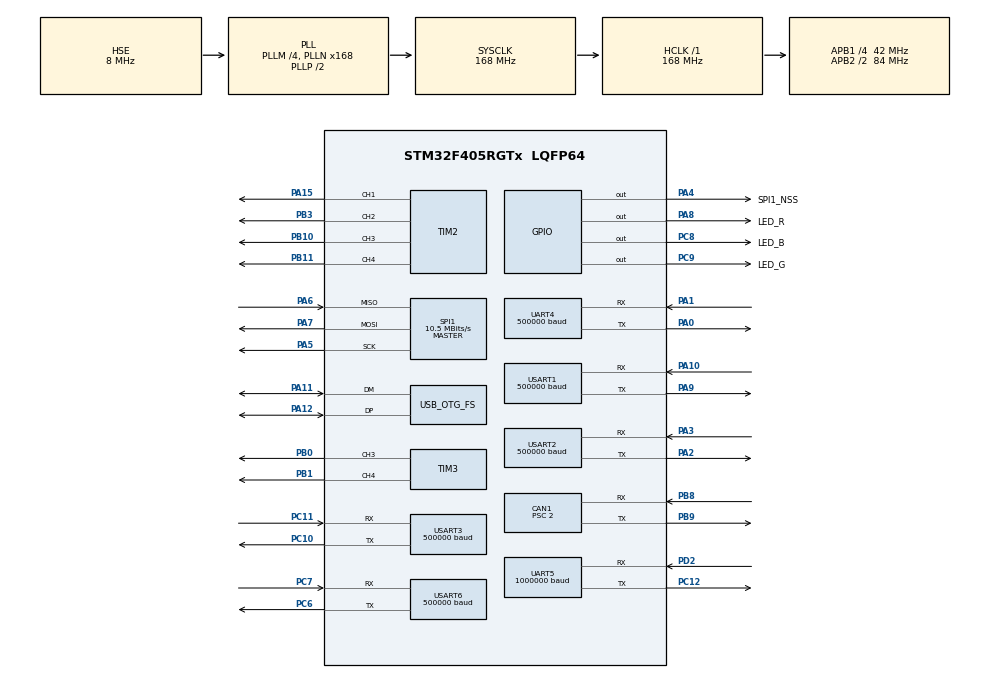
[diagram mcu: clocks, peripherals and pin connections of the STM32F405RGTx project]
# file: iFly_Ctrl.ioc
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CAN1.BS1=CAN_BS1_16TQ
CAN1.BS2=CAN_BS2_4TQ
CAN1.CalculateBaudRate=1000000
CAN1.CalculateTimeBit=1000
CAN1.CalculateTimeQuantum=47.61904761904762
CAN1.Mode=CAN_MODE_LOOPBACK
CAN1.Prescaler=2
Dma.Request0=UART4_RX
Dma.Request1=UART4_TX
Dma.Request10=USART6_RX
Dma.Request11=USART6_TX
Dma.Request2=UART5_RX
Dma.Request3=UART5_TX
Dma.Request4=USART1_RX
Dma.Request5=USART1_TX
Dma.Request6=USART2_RX
Dma.Request7=USART2_TX
Dma.Request8=USART3_RX
Dma.Request9=USART3_TX
Dma.UART4_RX.0.Direction=DMA_PERIPH_TO_MEMORY
Dma.UART4_RX.0.FIFOMode=DMA_FIFOMODE_DISABLE
Dma.UART4_RX.0.Instance=DMA1_Stream2
Dma.UART4_RX.0.MemDataAlignment=DMA_MDATAALIGN_BYTE
Dma.UART4_RX.0.MemInc=DMA_MINC_ENABLE
Dma.UART4_RX.0.Mode=DMA_CIRCULAR
Dma.UART4_RX.0.PeriphDataAlignment=DMA_PDATAALIGN_BYTE
Dma.UART4_RX.0.PeriphInc=DMA_PINC_DISABLE
Dma.UART4_RX.0.Priority=DMA_PRIORITY_LOW
Dma.UART4_TX.1.Direction=DMA_MEMORY_TO_PERIPH
Dma.UART4_TX.1.FIFOMode=DMA_FIFOMODE_DISABLE
Dma.UART4_TX.1.Instance=DMA1_Stream4
Dma.UART4_TX.1.MemDataAlignment=DMA_MDATAALIGN_BYTE
Dma.UART4_TX.1.MemInc=DMA_MINC_ENABLE
Dma.UART4_TX.1.Mode=DMA_NORMAL
Dma.UART4_TX.1.PeriphDataAlignment=DMA_PDATAALIGN_BYTE
Dma.UART4_TX.1.PeriphInc=DMA_PINC_DISABLE
Dma.UART4_TX.1.Priority=DMA_PRIORITY_LOW
Dma.UART5_RX.2.Direction=DMA_PERIPH_TO_MEMORY
Dma.UART5_RX.2.FIFOMode=DMA_FIFOMODE_DISABLE
Dma.UART5_RX.2.Instance=DMA1_Stream0
Dma.UART5_RX.2.MemDataAlignment=DMA_MDATAALIGN_BYTE
Dma.UART5_RX.2.MemInc=DMA_MINC_ENABLE
Dma.UART5_RX.2.Mode=DMA_CIRCULAR
Dma.UART5_RX.2.PeriphDataAlignment=DMA_PDATAALIGN_BYTE
Dma.UART5_RX.2.PeriphInc=DMA_PINC_DISABLE
Dma.UART5_RX.2.Priority=DMA_PRIORITY_LOW
Dma.UART5_TX.3.Direction=DMA_MEMORY_TO_PERIPH
Dma.UART5_TX.3.FIFOMode=DMA_FIFOMODE_DISABLE
Dma.UART5_TX.3.Instance=DMA1_Stream7
Dma.UART5_TX.3.MemDataAlignment=DMA_MDATAALIGN_BYTE
Dma.UART5_TX.3.MemInc=DMA_MINC_ENABLE
Dma.UART5_TX.3.Mode=DMA_NORMAL
Dma.UART5_TX.3.PeriphDataAlignment=DMA_PDATAALIGN_BYTE
Dma.UART5_TX.3.PeriphInc=DMA_PINC_DISABLE
Dma.UART5_TX.3.Priority=DMA_PRIORITY_LOW
Dma.USART1_RX.4.Direction=DMA_PERIPH_TO_MEMORY
Dma.USART1_RX.4.FIFOMode=DMA_FIFOMODE_DISABLE
Dma.USART1_RX.4.Instance=DMA2_Stream2
Dma.USART1_RX.4.MemDataAlignment=DMA_MDATAALIGN_BYTE
Dma.USART1_RX.4.MemInc=DMA_MINC_ENABLE
Dma.USART1_RX.4.Mode=DMA_CIRCULAR
Dma.USART1_RX.4.PeriphDataAlignment=DMA_PDATAALIGN_BYTE
Dma.USART1_RX.4.PeriphInc=DMA_PINC_DISABLE
Dma.USART1_RX.4.Priority=DMA_PRIORITY_LOW
Dma.USART1_TX.5.Direction=DMA_MEMORY_TO_PERIPH
Dma.USART1_TX.5.FIFOMode=DMA_FIFOMODE_DISABLE
Dma.USART1_TX.5.Instance=DMA2_Stream7
Dma.USART1_TX.5.MemDataAlignment=DMA_MDATAALIGN_BYTE
Dma.USART1_TX.5.MemInc=DMA_MINC_ENABLE
Dma.USART1_TX.5.Mode=DMA_NORMAL
Dma.USART1_TX.5.PeriphDataAlignment=DMA_PDATAALIGN_BYTE
Dma.USART1_TX.5.PeriphInc=DMA_PINC_DISABLE
Dma.USART1_TX.5.Priority=DMA_PRIORITY_LOW
Dma.USART2_RX.6.Direction=DMA_PERIPH_TO_MEMORY
Dma.USART2_RX.6.FIFOMode=DMA_FIFOMODE_DISABLE
Dma.USART2_RX.6.Instance=DMA1_Stream5
Dma.USART2_RX.6.MemDataAlignment=DMA_MDATAALIGN_BYTE
Dma.USART2_RX.6.MemInc=DMA_MINC_ENABLE
Dma.USART2_RX.6.Mode=DMA_CIRCULAR
Dma.USART2_RX.6.PeriphDataAlignment=DMA_PDATAALIGN_BYTE
Dma.USART2_RX.6.PeriphInc=DMA_PINC_DISABLE
Dma.USART2_RX.6.Priority=DMA_PRIORITY_LOW
Dma.USART2_TX.7.Direction=DMA_MEMORY_TO_PERIPH
Dma.USART2_TX.7.FIFOMode=DMA_FIFOMODE_DISABLE
Dma.USART2_TX.7.Instance=DMA1_Stream6
Dma.USART2_TX.7.MemDataAlignment=DMA_MDATAALIGN_BYTE
Dma.USART2_TX.7.MemInc=DMA_MINC_ENABLE
Dma.USART2_TX.7.Mode=DMA_NORMAL
Dma.USART2_TX.7.PeriphDataAlignment=DMA_PDATAALIGN_BYTE
Dma.USART2_TX.7.PeriphInc=DMA_PINC_DISABLE
Dma.USART2_TX.7.Priority=DMA_PRIORITY_LOW
Dma.USART3_RX.8.Direction=DMA_PERIPH_TO_MEMORY
Dma.USART3_RX.8.FIFOMode=DMA_FIFOMODE_DISABLE
Dma.USART3_RX.8.Instance=DMA1_Stream1
Dma.USART3_RX.8.MemDataAlignment=DMA_MDATAALIGN_BYTE
Dma.USART3_RX.8.MemInc=DMA_MINC_ENABLE
Dma.USART3_RX.8.Mode=DMA_CIRCULAR
Dma.USART3_RX.8.PeriphDataAlignment=DMA_PDATAALIGN_BYTE
Dma.USART3_RX.8.PeriphInc=DMA_PINC_DISABLE
Dma.USART3_RX.8.Priority=DMA_PRIORITY_LOW
Dma.USART3_TX.9.Direction=DMA_MEMORY_TO_PERIPH
Dma.USART3_TX.9.FIFOMode=DMA_FIFOMODE_DISABLE
Dma.USART3_TX.9.Instance=DMA1_Stream3
Dma.USART3_TX.9.MemDataAlignment=DMA_MDATAALIGN_BYTE
Dma.USART3_TX.9.MemInc=DMA_MINC_ENABLE
Dma.USART3_TX.9.Mode=DMA_NORMAL
Dma.USART3_TX.9.PeriphDataAlignment=DMA_PDATAALIGN_BYTE
Dma.USART3_TX.9.PeriphInc=DMA_PINC_DISABLE
Dma.USART3_TX.9.Priority=DMA_PRIORITY_LOW
Dma.USART6_RX.10.Direction=DMA_PERIPH_TO_MEMORY
Dma.USART6_RX.10.FIFOMode=DMA_FIFOMODE_DISABLE
Dma.USART6_RX.10.Instance=DMA2_Stream1
Dma.USART6_RX.10.MemDataAlignment=DMA_MDATAALIGN_BYTE
Dma.USART6_RX.10.MemInc=DMA_MINC_ENABLE
Dma.USART6_RX.10.Mode=DMA_CIRCULAR
Dma.USART6_RX.10.PeriphDataAlignment=DMA_PDATAALIGN_BYTE
Dma.USART6_RX.10.PeriphInc=DMA_PINC_DISABLE
Dma.USART6_RX.10.Priority=DMA_PRIORITY_LOW
Dma.USART6_TX.11.Direction=DMA_MEMORY_TO_PERIPH
Dma.USART6_TX.11.FIFOMode=DMA_FIFOMODE_DISABLE
Dma.USART6_TX.11.Instance=DMA2_Stream6
Dma.USART6_TX.11.MemDataAlignment=DMA_MDATAALIGN_BYTE
Dma.USART6_TX.11.MemInc=DMA_MINC_ENABLE
Dma.USART6_TX.11.Mode=DMA_NORMAL
Dma.USART6_TX.11.PeriphDataAlignment=DMA_PDATAALIGN_BYTE
Dma.USART6_TX.11.PeriphInc=DMA_PINC_DISABLE
Dma.USART6_TX.11.Priority=DMA_PRIORITY_LOW
Mcu.Family=STM32F4
Mcu.Name=STM32F405RGTx
Mcu.Package=LQFP64
NVIC.CAN1_RX0_IRQn=true\:0\:0\:false\:false\:true\:true\:true\:true
NVIC.CAN1_RX1_IRQn=true\:0\:0\:false\:false\:true\:true\:true\:true
NVIC.CAN1_SCE_IRQn=true\:0\:0\:false\:false\:true\:true\:true\:true
NVIC.CAN1_TX_IRQn=true\:0\:0\:true\:false\:true\:true\:true\:true
NVIC.DMA1_Stream0_IRQn=true\:0\:0\:false\:false\:true\:false\:true\:true
NVIC.DMA1_Stream1_IRQn=true\:0\:0\:false\:false\:true\:false\:true\:true
NVIC.DMA1_Stream2_IRQn=true\:0\:0\:false\:false\:true\:false\:true\:true
NVIC.DMA1_Stream3_IRQn=true\:0\:0\:false\:false\:true\:false\:true\:true
NVIC.DMA1_Stream4_IRQn=true\:0\:0\:false\:false\:true\:false\:true\:true
NVIC.DMA1_Stream5_IRQn=true\:0\:0\:false\:false\:true\:false\:true\:true
NVIC.DMA1_Stream6_IRQn=true\:0\:0\:false\:false\:true\:false\:true\:true
NVIC.DMA1_Stream7_IRQn=true\:0\:0\:false\:false\:true\:false\:true\:true
NVIC.DMA2_Stream1_IRQn=true\:0\:0\:false\:false\:true\:false\:true\:true
NVIC.DMA2_Stream2_IRQn=true\:0\:0\:false\:false\:true\:false\:true\:true
NVIC.DMA2_Stream6_IRQn=true\:0\:0\:false\:false\:true\:false\:true\:true
NVIC.DMA2_Stream7_IRQn=true\:0\:0\:false\:false\:true\:false\:true\:true
NVIC.OTG_FS_IRQn=true\:0\:0\:false\:false\:true\:true\:true\:true
NVIC.PriorityGroup=NVIC_PRIORITYGROUP_4
NVIC.UART4_IRQn=true\:1\:0\:true\:false\:true\:true\:true\:true
NVIC.UART5_IRQn=true\:1\:0\:true\:false\:true\:true\:true\:true
NVIC.USART1_IRQn=true\:1\:0\:true\:false\:true\:true\:true\:true
NVIC.USART2_IRQn=true\:1\:0\:true\:false\:true\:true\:true\:true
NVIC.USART3_IRQn=true\:1\:0\:true\:false\:true\:true\:true\:true
NVIC.USART6_IRQn=true\:1\:0\:true\:false\:true\:true\:true\:true
PA0-WKUP.Mode=Asynchronous
PA0-WKUP.Signal=UART4_TX
PA1.Mode=Asynchronous
PA1.Signal=UART4_RX
PA10.Mode=Asynchronous
PA10.Signal=USART1_RX
PA11.Mode=Device_Only
PA11.Signal=USB_OTG_FS_DM
PA12.Mode=Device_Only
PA12.Signal=USB_OTG_FS_DP
PA13.Mode=Serial_Wire
PA13.Signal=SYS_JTMS-SWDIO
PA14.Mode=Serial_Wire
PA14.Signal=SYS_JTCK-SWCLK
PA15.Signal=S_TIM2_CH1_ETR
PA2.Mode=Asynchronous
PA2.Signal=USART2_TX
PA3.Mode=Asynchronous
PA3.Signal=USART2_RX
PA4.GPIO_Label=SPI1_NSS
PA4.Signal=GPIO_Output
PA5.Mode=Full_Duplex_Master
PA5.Signal=SPI1_SCK
PA6.Mode=Full_Duplex_Master
PA6.Signal=SPI1_MISO
PA7.Mode=Full_Duplex_Master
PA7.Signal=SPI1_MOSI
PA8.GPIO_Label=LED_R
PA8.Signal=GPIO_Output
PA9.Mode=Asynchronous
PA9.Signal=USART1_TX
PB0.Signal=S_TIM3_CH3
PB1.Signal=S_TIM3_CH4
PB10.Signal=S_TIM2_CH3
PB11.Signal=S_TIM2_CH4
PB3.Signal=S_TIM2_CH2
PB8.Mode=CAN_Activate
PB8.Signal=CAN1_RX
PB9.Mode=CAN_Activate
PB9.Signal=CAN1_TX
PC10.Mode=Asynchronous
PC10.Signal=USART3_TX
PC11.Mode=Asynchronous
PC11.Signal=USART3_RX
PC12.Mode=Asynchronous
PC12.Signal=UART5_TX
PC6.Mode=Asynchronous
PC6.Signal=USART6_TX
PC7.Mode=Asynchronous
PC7.Signal=USART6_RX
PC8.GPIO_Label=LED_B
PC8.Signal=GPIO_Output
PC9.GPIO_Label=LED_G
PC9.Signal=GPIO_Output
PD2.Mode=Asynchronous
PD2.Signal=UART5_RX
PH0-OSC_IN.Mode=HSE-External-Oscillator
PH0-OSC_IN.Signal=RCC_OSC_IN
PH1-OSC_OUT.Mode=HSE-External-Oscillator
PH1-OSC_OUT.Signal=RCC_OSC_OUT
ProjectManager.HeapSize=0x200
ProjectManager.StackSize=0x400
ProjectManager.TargetToolchain=CMake
RCC.48MHZClocksFreq_Value=48000000
RCC.AHBFreq_Value=168000000
RCC.APB1CLKDivider=RCC_HCLK_DIV4
RCC.APB1Freq_Value=42000000
RCC.APB1TimFreq_Value=84000000
RCC.APB2CLKDivider=RCC_HCLK_DIV2
RCC.APB2Freq_Value=84000000
RCC.APB2TimFreq_Value=168000000
RCC.CortexFreq_Value=168000000
RCC.HCLKFreq_Value=168000000
RCC.HSE_VALUE=8000000
RCC.HSI_VALUE=16000000
RCC.LSE_VALUE=32768
RCC.PLLM=4
RCC.PLLN=168
RCC.PLLQ=7
RCC.SYSCLKFreq_VALUE=168000000
RCC.SYSCLKSource=RCC_SYSCLKSOURCE_PLLCLK
RCC.VCOOutputFreq_Value=336000000
SH.S_TIM2_CH1_ETR.0=TIM2_CH1,PWM Generation1 CH1
SH.S_TIM2_CH2.0=TIM2_CH2,PWM Generation2 CH2
SH.S_TIM2_CH3.0=TIM2_CH3,PWM Generation3 CH3
SH.S_TIM2_CH4.0=TIM2_CH4,PWM Generation4 CH4
SH.S_TIM3_CH3.0=TIM3_CH3,PWM Generation3 CH3
SH.S_TIM3_CH4.0=TIM3_CH4,PWM Generation4 CH4
SPI1.BaudRatePrescaler=SPI_BAUDRATEPRESCALER_8
SPI1.CalculateBaudRate=10.5 MBits/s
SPI1.Direction=SPI_DIRECTION_2LINES
SPI1.Mode=SPI_MODE_MASTER
SPI1.VirtualType=VM_MASTER
TIM2.Channel-PWM\ Generation1\ CH1=TIM_CHANNEL_1
TIM2.Channel-PWM\ Generation2\ CH2=TIM_CHANNEL_2
TIM2.Channel-PWM\ Generation3\ CH3=TIM_CHANNEL_3
TIM2.Channel-PWM\ Generation4\ CH4=TIM_CHANNEL_4
TIM3.Channel-PWM\ Generation1\ CH1=TIM_CHANNEL_1
TIM3.Channel-PWM\ Generation2\ CH2=TIM_CHANNEL_2
TIM3.Channel-PWM\ Generation3\ CH3=TIM_CHANNEL_3
TIM3.Channel-PWM\ Generation4\ CH4=TIM_CHANNEL_4
UART4.BaudRate=500000
UART4.VirtualMode=Asynchronous
UART5.BaudRate=1000000
UART5.VirtualMode=Asynchronous
USART1.BaudRate=500000
USART1.VirtualMode=VM_ASYNC
USART2.BaudRate=500000
USART2.VirtualMode=VM_ASYNC
USART3.BaudRate=500000
USART3.VirtualMode=VM_ASYNC
USART6.BaudRate=500000
USART6.VirtualMode=VM_ASYNC
USB_OTG_FS.VirtualMode=Device_Only
VP_TIM2_VS_ClockSourceINT.Mode=Internal
VP_TIM3_VS_ClockSourceINT.Mode=Internal
board=custom

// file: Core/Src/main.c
/* USER CODE BEGIN Header */
/**
  ******************************************************************************
  * @file           : main.c
  * @brief          : Main program body
  ******************************************************************************
  * @attention
  *
  * Copyright (c) 2026 STMicroelectronics.
  * All rights reserved.
  *
  * This software is licensed under terms that can be found in the LICENSE file
  * in the root directory of this software component.
  * If no LICENSE file comes with this software, it is provided AS-IS.
  *
  ******************************************************************************
  */
/* USER CODE END Header */
#include "main.h"
#include "can.h"
#include "dma.h"
#include "spi.h"
#include "tim.h"
#include "usart.h"
#include "usb_otg.h"
#include "gpio.h"

/* USER CODE BEGIN Includes */
#include "app_main.h"

/* USER CODE END Includes */

void SystemClock_Config(void);

int main(void)
{

  /* MCU Configuration--------------------------------------------------------*/

  /* Reset of all peripherals, Initializes the Flash interface and the Systick. */
  HAL_Init();

  /* Configure the system clock */
  SystemClock_Config();

  /* Initialize all configured peripherals */
  MX_GPIO_Init();
  MX_DMA_Init();
  MX_USB_OTG_FS_PCD_Init();
  MX_UART4_Init();
  MX_UART5_Init();
  MX_USART1_UART_Init();
  MX_USART2_UART_Init();
  MX_USART3_UART_Init();
  MX_USART6_UART_Init();
  MX_CAN1_Init();
  MX_TIM2_Init();
  MX_TIM3_Init();
  MX_SPI1_Init();
  /* USER CODE BEGIN 2 */
  /*
   * 上层应用逻辑放在 C++ 文件 `iFly/app_main.cpp` 中。
   *
   * main.c 仍然保留为 CubeMX 工程的启动入口，
   * 后续只需要在主循环中持续调用 app_main() 即可。
   */
  app_main();
  /* USER CODE END 2 */

  /* Infinite loop */
  while (1)
  {

    /* USER CODE BEGIN 3 */

    //HAL_Delay(1);
  }
  /* USER CODE END 3 */
}

void SystemClock_Config(void)
{
  RCC_OscInitTypeDef RCC_OscInitStruct = {0};
  RCC_ClkInitTypeDef RCC_ClkInitStruct = {0};

  /** Configure the main internal regulator output voltage
  */
  __HAL_RCC_PWR_CLK_ENABLE();
  __HAL_PWR_VOLTAGESCALING_CONFIG(PWR_REGULATOR_VOLTAGE_SCALE1);

  /** Initializes the RCC Oscillators according to the specified parameters
  * in the RCC_OscInitTypeDef structure.
  */
  RCC_OscInitStruct.OscillatorType = RCC_OSCILLATORTYPE_HSE;
  RCC_OscInitStruct.HSEState = RCC_HSE_ON;
  RCC_OscInitStruct.PLL.PLLState = RCC_PLL_ON;
  RCC_OscInitStruct.PLL.PLLSource = RCC_PLLSOURCE_HSE;
  RCC_OscInitStruct.PLL.PLLM = 4;
  RCC_OscInitStruct.PLL.PLLN = 168;
  RCC_OscInitStruct.PLL.PLLP = RCC_PLLP_DIV2;
  RCC_OscInitStruct.PLL.PLLQ = 7;
  if (HAL_RCC_OscConfig(&RCC_OscInitStruct) != HAL_OK)
  {
    Error_Handler();
  }

  /** Initializes the CPU, AHB and APB buses clocks
  */
  RCC_ClkInitStruct.ClockType = RCC_CLOCKTYPE_HCLK|RCC_CLOCKTYPE_SYSCLK
                              |RCC_CLOCKTYPE_PCLK1|RCC_CLOCKTYPE_PCLK2;
  RCC_ClkInitStruct.SYSCLKSource = RCC_SYSCLKSOURCE_PLLCLK;
  RCC_ClkInitStruct.AHBCLKDivider = RCC_SYSCLK_DIV1;
  RCC_ClkInitStruct.APB1CLKDivider = RCC_HCLK_DIV4;
  RCC_ClkInitStruct.APB2CLKDivider = RCC_HCLK_DIV2;

  if (HAL_RCC_ClockConfig(&RCC_ClkInitStruct, FLASH_LATENCY_5) != HAL_OK)
  {
    Error_Handler();
  }
}

void Error_Handler(void)
{
  __disable_irq();
  while (1)
  {
  }
}
